# R7FA6T2BD register map
Vendor: Renesas Electronics Corporation; Series: RA6; File version: 1.30.01
CPU: CM33 r0p4, little endian, MPU, FPU, VTOR, 4 interrupt priority bits, 96 interrupts
Registers are 32-bit, read-write, reset 0x0 unless marked. A register's access mark holds for its fields unless they carry their own. Offsets are from the block's base; [hi:lo] are bit positions; {n}, {i} and the like mark numbered series.

## TFU — Trigonometric Function Unit
Base 0x40021000
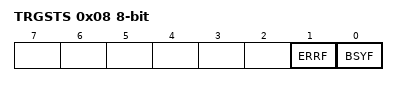
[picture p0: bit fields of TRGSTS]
0x08 TRGSTS 8-bit ro — Trigonometric Status Register
  [1] ERRF — Input error flag
    0=No input error occurred; 1=Input error occurred
  [0] BSYF — Calculation in progress flag
    0=No calculating; 1=Calculating
0x10 SCDT0 — Sine Cosine Data Register 0
  [31:0] SCDT0 — Sine Cosine Data Register 0 (single-precision floating-point)
0x14 SCDT1 — Sine Cosine Data Register 1
  [31:0] SCDT1 — Sine Cosine Data Register 1 (single-precision floating-point)
0x18 ATDT0 — Arctangent Data Register 0
  [31:0] ATDT0 — Arctangent Data Register 0 (single-precision floating-point)
0x1C ATDT1 — Arctangent Data Register 1
  [31:0] ATDT1 — Arctangent Data Register 1 (single-precision floating-point)

## ELC_B — Event Link Controller
Base 0x40082000
0x00 ELCR 8-bit — Event Link Controller Register
  [7] ELCON — All Event Link Enable
    0=ELC function is disabled; 1=ELC function is enabled
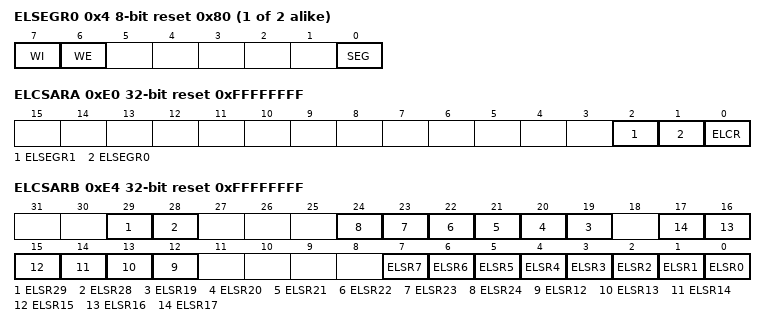
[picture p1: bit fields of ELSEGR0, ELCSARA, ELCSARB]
{0x4+4i} ELSEGR{i} (i=0..1) 8-bit reset 0x80 — Event Link Software Event Generation Register {i}
  [7] WI wo — ELSEGR Register Write Disable
    0=Write to ELSEGR register enabled; 1=Write to ELSEGR register disabled
  [6] WE — SEG Bit Write Enable
    0=Write to SEG bit disabled; 1=Write to SEG bit enabled
  [0] SEG wo — Software Event Generation
    0=Normal operation; 1=Software event is generated
{0x20+4i} ELSR{i} (i=0..7) 16-bit — Event Link Setting Register {i}
  [8:0] ELS — Event Link Select
{0x20+4i} ELSR{i} (i=12..17) 16-bit — Event Link Setting Register {i}
  [8:0] ELS — Event Link Select
{0x20+4i} ELSR{i} (i=19..24) 16-bit — Event Link Setting Register {i}
  [8:0] ELS — Event Link Select
{0x20+4i} ELSR{i} (i=28..29) 16-bit — Event Link Setting Register {i}
  [8:0] ELS — Event Link Select
0xE0 ELCSARA reset 0xFFFFFFFF — Event Link Controller Security Attribution Register A
  [all] fields
    0=Secure; 1=Non-secure
  [2] ELSEGR1 — Event Link Software Event Generation Register 1 Security Attribution
  [1] ELSEGR0 — Event Link Software Event Generation Register 0 Security Attribution
  [0] ELCR — Event Link Controller Register Security Attribution
0xE4 ELCSARB reset 0xFFFFFFFF — Event Link Controller Security Attribution Register B
  [all] fields
    0=Secure; 1=Non-secure
  [29] ELSR29 — Event Link Setting Register n Security Attribution
  [28] ELSR28 — Event Link Setting Register n Security Attribution
  [n] ELSR{n} (n=19..24) — Event Link Setting Register n Security Attribution
  [n] ELSR{n} (n=12..17) — Event Link Setting Register n Security Attribution
  [n] ELSR{n} (n=0..7) — Event Link Setting Register n Security Attribution

## IWDT — Independent Watchdog Timer
Base 0x40083200
0x00 IWDTRR 8-bit reset 0xFF — IWDT Refresh Register
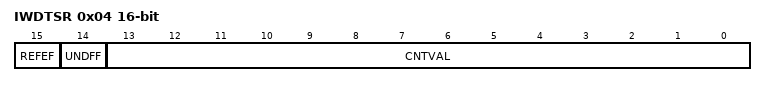
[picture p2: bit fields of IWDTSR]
0x04 IWDTSR 16-bit — IWDT Status Register
  [15] REFEF — Refresh Error Flag
    0=No refresh error occurred; 1=Refresh error occurred
  [14] UNDFF — Underflow Flag
    0=No underflow occurred; 1=Underflow occurred
  [13:0] CNTVAL ro — Down-counter Value

## WDT — Watchdog Timer
Base 0x40083400
0x00 WDTRR 8-bit reset 0xFF — WDT Refresh Register
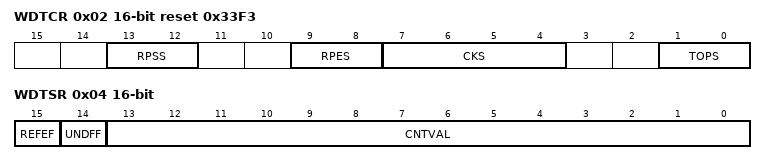
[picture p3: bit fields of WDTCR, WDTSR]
0x02 WDTCR 16-bit reset 0x33F3 — WDT Control Register
  [13:12] RPSS — Window Start Position Select
    0=25%; 1=50%; 2=75%; 3=100% (do not specify window start position)
  [9:8] RPES — Window End Position Select
    0=75%; 1=50%; 2=25%; 3=0% (do not specify window end position)
  [7:4] CKS — Clock Division Ratio Select
    1=PCLKB/4; 4=PCLKB/64; 15=PCLKB/128; 6=PCLKB/512; 7=PCLKB/2048; 8=PCLKB/8192; other=Others (Setting prohibited)
  [1:0] TOPS — Timeout Period Select
    0=1024 cycles (0x03FF); 1=4096 cycles (0x0FFF); 2=8192 cycles (0x1FFF); 3=16384 cycles (0x3FFF)
0x04 WDTSR 16-bit — WDT Status Register
  [15] REFEF — Refresh Error Flag
    0=No refresh error occurred; 1=Refresh error occurred
  [14] UNDFF — Underflow Flag
    0=No underflow occurred; 1=Underflow occurred
  [13:0] CNTVAL ro — Down-Counter Value
0x06 WDTRCR 8-bit reset 0x80 — WDT Reset Control Register
  [7] RSTIRQS — Reset Interrupt Request Select
    0=Enable non-maskable interrupt request or interrupt request output; 1=Enable reset output
0x08 WDTCSTPR 8-bit reset 0x80 — WDT Count Stop Control Register
  [7] SLCSTP
    0=Disable count stop; 1=Stop count on transition to Sleep mode
